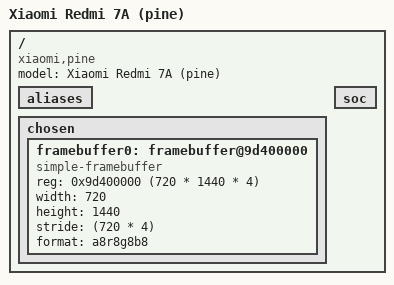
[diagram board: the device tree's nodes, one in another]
/dts-v1/;

#include "sdm439.dtsi"

/ {
	model = "Xiaomi Redmi 7A (pine)";
	compatible = "xiaomi,pine", "qcom,sdm439";

	#address-cells = <2>;
	#size-cells = <2>;

	aliases {};

	chosen {
		#address-cells = <1>;
		#size-cells = <1>;

		framebuffer0: framebuffer@9d400000 {
			compatible = "simple-framebuffer";
			reg = <0x9d400000 (720 * 1440 * 4)>;
			width = <720>;
			height = <1440>;
			stride = <(720 * 4)>;
			format = "a8r8g8b8";
		};
	};

	soc {
		ranges = <0 0 0 0xffffffff>;
	};
};
